# PIC32MX250F128C register map
Registers are 32-bit, access not given, reset 0x0 unless marked. A register's access mark holds for its fields unless they carry their own. Offsets are from the block's base; [hi:lo] are bit positions; 'fields as' and 'values as' point back to an identical list.

## DMAC1 — DMAC1 peripheral
Base 0xBF883120
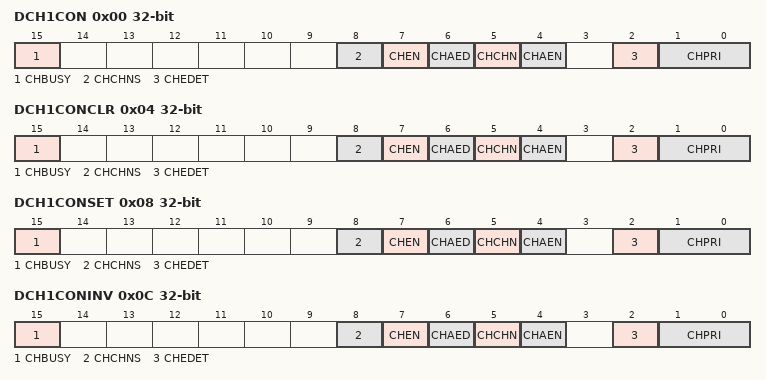
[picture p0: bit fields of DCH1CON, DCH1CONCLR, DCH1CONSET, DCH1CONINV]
0x00 DCH1CON
  [15] CHBUSY, [8] CHCHNS, [7] CHEN, [6] CHAED, [5] CHCHN, [4] CHAEN, [2] CHEDET, [1:0] CHPRI
0x04 DCH1CONCLR
  fields as DCH1CON
0x08 DCH1CONSET
  fields as DCH1CON
0x0C DCH1CONINV
  fields as DCH1CON
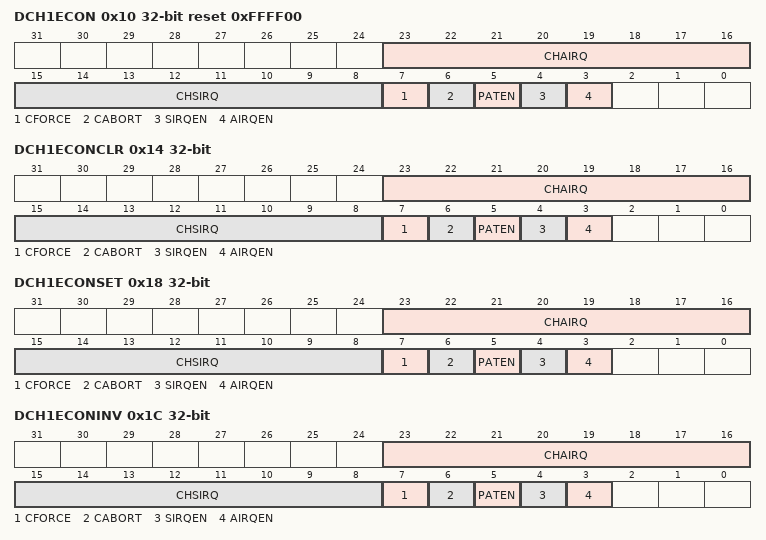
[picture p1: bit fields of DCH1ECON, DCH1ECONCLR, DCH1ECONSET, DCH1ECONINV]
0x10 DCH1ECON reset 0xFFFF00
  [23:16] CHAIRQ, [15:8] CHSIRQ, [7] CFORCE, [6] CABORT, [5] PATEN, [4] SIRQEN, [3] AIRQEN
0x14 DCH1ECONCLR
  fields as DCH1ECON
0x18 DCH1ECONSET
  fields as DCH1ECON
0x1C DCH1ECONINV
  fields as DCH1ECON
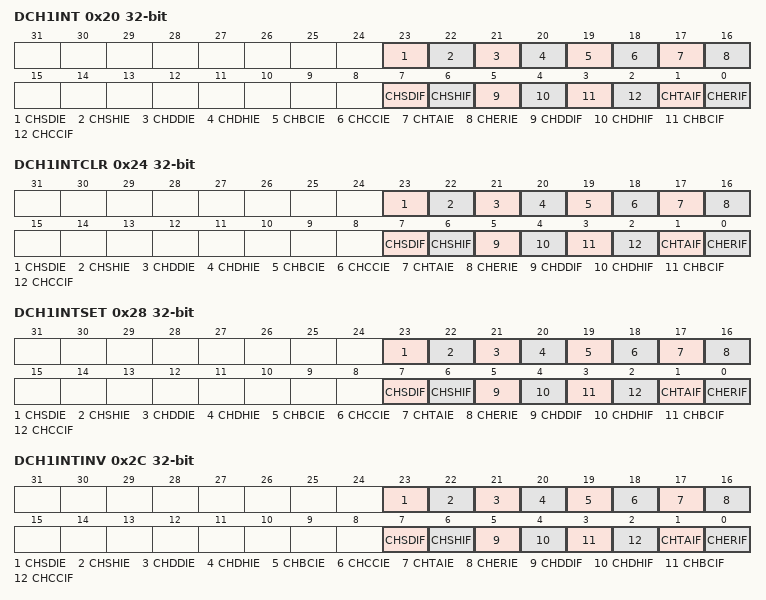
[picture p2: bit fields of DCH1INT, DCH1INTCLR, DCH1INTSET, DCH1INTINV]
0x20 DCH1INT
  [23] CHSDIE, [22] CHSHIE, [21] CHDDIE, [20] CHDHIE, [19] CHBCIE, [18] CHCCIE, [17] CHTAIE, [16] CHERIE, [7] CHSDIF, [6] CHSHIF, [5] CHDDIF, [4] CHDHIF, [3] CHBCIF, [2] CHCCIF, [1] CHTAIF, [0] CHERIF
0x24 DCH1INTCLR
  fields as DCH1INT
0x28 DCH1INTSET
  fields as DCH1INT
0x2C DCH1INTINV
  fields as DCH1INT
0x30 DCH1SSA
0x34 DCH1SSACLR
  [31:0] DCH1SSA
0x38 DCH1SSASET
  [31:0] DCH1SSA
0x3C DCH1SSAINV
  [31:0] DCH1SSA
0x40 DCH1DSA
0x44 DCH1DSACLR
  [31:0] DCH1DSA
0x48 DCH1DSASET
  [31:0] DCH1DSA
0x4C DCH1DSAINV
  [31:0] DCH1DSA
0x50 DCH1SSIZ
  [15:0] CHSSIZ
0x54 DCH1SSIZCLR
  [15:0] CHSSIZ
0x58 DCH1SSIZSET
  [15:0] CHSSIZ
0x5C DCH1SSIZINV
  [15:0] CHSSIZ
0x60 DCH1DSIZ
  [15:0] CHDSIZ
0x64 DCH1DSIZCLR
  [15:0] CHDSIZ
0x68 DCH1DSIZSET
  [15:0] CHDSIZ
0x6C DCH1DSIZINV
  [15:0] CHDSIZ
0x70 DCH1SPTR
  [15:0] CHSPTR
0x74 DCH1SPTRCLR
  [15:0] CHSPTR
0x78 DCH1SPTRSET
  [15:0] CHSPTR
0x7C DCH1SPTRINV
  [15:0] CHSPTR
0x80 DCH1DPTR
  [15:0] CHDPTR
0x84 DCH1DPTRCLR
  [15:0] CHDPTR
0x88 DCH1DPTRSET
  [15:0] CHDPTR
0x8C DCH1DPTRINV
  [15:0] CHDPTR
0x90 DCH1CSIZ
  [15:0] CHCSIZ
0x94 DCH1CSIZCLR
  [15:0] CHCSIZ
0x98 DCH1CSIZSET
  [15:0] CHCSIZ
0x9C DCH1CSIZINV
  [15:0] CHCSIZ
0xA0 DCH1CPTR
  [15:0] CHCPTR
0xA4 DCH1CPTRCLR
  [15:0] CHCPTR
0xA8 DCH1CPTRSET
  [15:0] CHCPTR
0xAC DCH1CPTRINV
  [15:0] CHCPTR
0xB0 DCH1DAT
  [7:0] DCHPDAT
0xB4 DCH1DATCLR
  [7:0] DCHPDAT
0xB8 DCH1DATSET
  [7:0] DCHPDAT
0xBC DCH1DATINV
  [7:0] DCHPDAT

## DMAC2 — DMAC2 peripheral
Base 0xBF8831E0
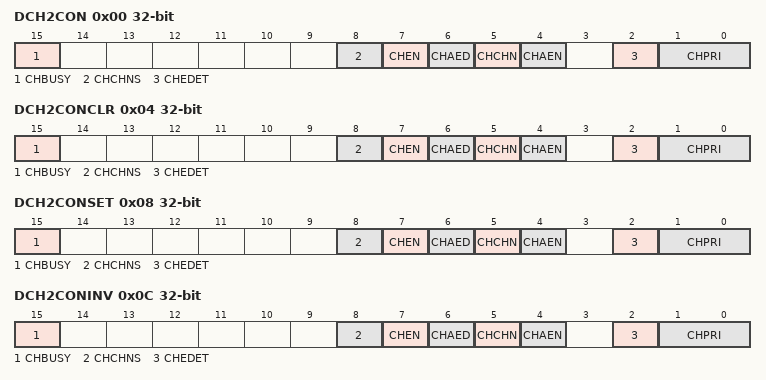
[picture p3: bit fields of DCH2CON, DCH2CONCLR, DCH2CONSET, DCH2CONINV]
0x00 DCH2CON
  [15] CHBUSY, [8] CHCHNS, [7] CHEN, [6] CHAED, [5] CHCHN, [4] CHAEN, [2] CHEDET, [1:0] CHPRI
0x04 DCH2CONCLR
  fields as DCH2CON
0x08 DCH2CONSET
  fields as DCH2CON
0x0C DCH2CONINV
  fields as DCH2CON
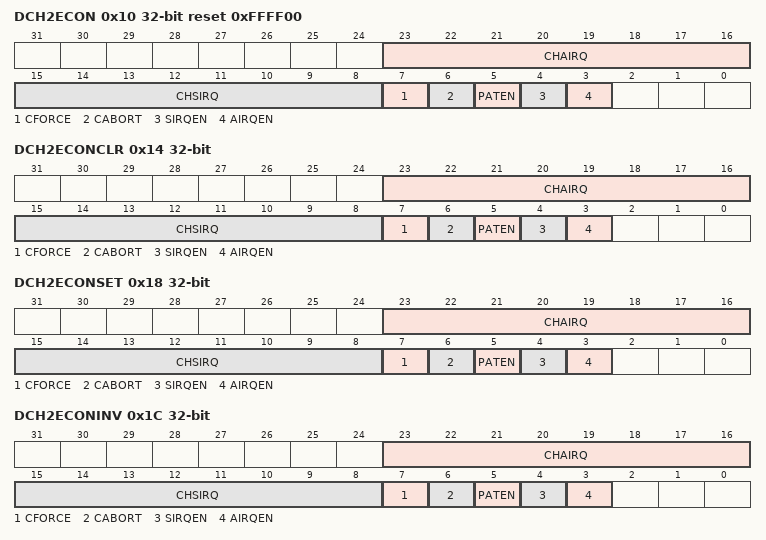
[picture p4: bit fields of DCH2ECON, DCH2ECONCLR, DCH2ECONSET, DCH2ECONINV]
0x10 DCH2ECON reset 0xFFFF00
  [23:16] CHAIRQ, [15:8] CHSIRQ, [7] CFORCE, [6] CABORT, [5] PATEN, [4] SIRQEN, [3] AIRQEN
0x14 DCH2ECONCLR
  fields as DCH2ECON
0x18 DCH2ECONSET
  fields as DCH2ECON
0x1C DCH2ECONINV
  fields as DCH2ECON
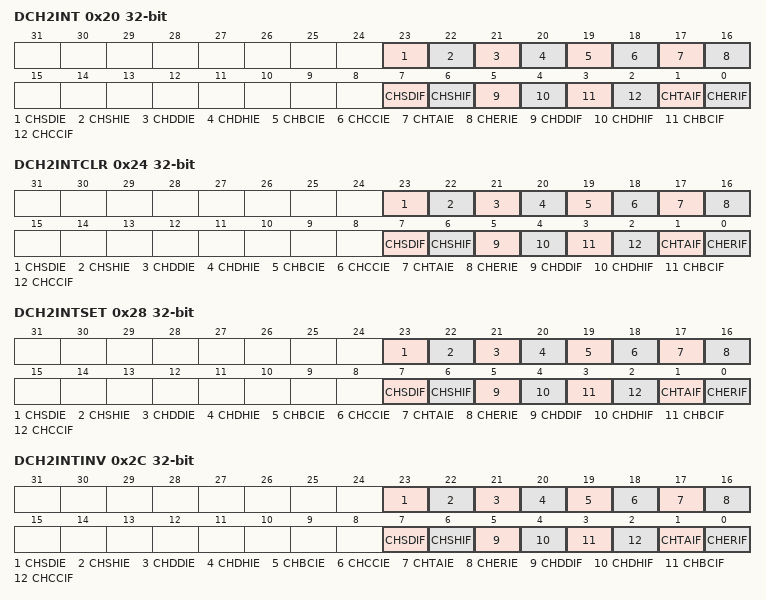
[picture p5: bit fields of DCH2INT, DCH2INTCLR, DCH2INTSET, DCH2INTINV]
0x20 DCH2INT
  [23] CHSDIE, [22] CHSHIE, [21] CHDDIE, [20] CHDHIE, [19] CHBCIE, [18] CHCCIE, [17] CHTAIE, [16] CHERIE, [7] CHSDIF, [6] CHSHIF, [5] CHDDIF, [4] CHDHIF, [3] CHBCIF, [2] CHCCIF, [1] CHTAIF, [0] CHERIF
0x24 DCH2INTCLR
  fields as DCH2INT
0x28 DCH2INTSET
  fields as DCH2INT
0x2C DCH2INTINV
  fields as DCH2INT
0x30 DCH2SSA
0x34 DCH2SSACLR
  [31:0] DCH2SSA
0x38 DCH2SSASET
  [31:0] DCH2SSA
0x3C DCH2SSAINV
  [31:0] DCH2SSA
0x40 DCH2DSA
0x44 DCH2DSACLR
  [31:0] DCH2DSA
0x48 DCH2DSASET
  [31:0] DCH2DSA
0x4C DCH2DSAINV
  [31:0] DCH2DSA
0x50 DCH2SSIZ
  [15:0] CHSSIZ
0x54 DCH2SSIZCLR
  [15:0] CHSSIZ
0x58 DCH2SSIZSET
  [15:0] CHSSIZ
0x5C DCH2SSIZINV
  [15:0] CHSSIZ
0x60 DCH2DSIZ
  [15:0] CHDSIZ
0x64 DCH2DSIZCLR
  [15:0] CHDSIZ
0x68 DCH2DSIZSET
  [15:0] CHDSIZ
0x6C DCH2DSIZINV
  [15:0] CHDSIZ
0x70 DCH2SPTR
  [15:0] CHSPTR
0x74 DCH2SPTRCLR
  [15:0] CHSPTR
0x78 DCH2SPTRSET
  [15:0] CHSPTR
0x7C DCH2SPTRINV
  [15:0] CHSPTR
0x80 DCH2DPTR
  [15:0] CHDPTR
0x84 DCH2DPTRCLR
  [15:0] CHDPTR
0x88 DCH2DPTRSET
  [15:0] CHDPTR
0x8C DCH2DPTRINV
  [15:0] CHDPTR
0x90 DCH2CSIZ
  [15:0] CHCSIZ
0x94 DCH2CSIZCLR
  [15:0] CHCSIZ
0x98 DCH2CSIZSET
  [15:0] CHCSIZ
0x9C DCH2CSIZINV
  [15:0] CHCSIZ
0xA0 DCH2CPTR
  [15:0] CHCPTR
0xA4 DCH2CPTRCLR
  [15:0] CHCPTR
0xA8 DCH2CPTRSET
  [15:0] CHCPTR
0xAC DCH2CPTRINV
  [15:0] CHCPTR
0xB0 DCH2DAT
  [7:0] DCHPDAT
0xB4 DCH2DATCLR
  [7:0] DCHPDAT
0xB8 DCH2DATSET
  [7:0] DCHPDAT
0xBC DCH2DATINV
  [7:0] DCHPDAT
